AUTOSAR XML (schema 4-0-3)
standard types defined: UInt32, UInt8
package /AUTOSAR_Platform/DataConstrs
  range DC_UInt8: raw 0..255
package /PATAC/MSM/ComponentTypes
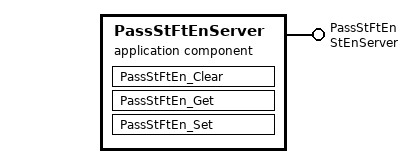
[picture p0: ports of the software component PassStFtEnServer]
  application sw component type PassStFtEnServer
    provide port PassStFtEn: provided-com-specs=[{operation=Clear, queue-length=1}, {operation=Get, queue-length=1}, {operation=Set, queue-length=1}], provided-interface=StEnServer
    behavior PassStFtEnServer_InternalBehavior
      operation invoked event OIT_PassStFtEn_Clear_PassStFtEn_Clear: start-on-event=PassStFtEn_Clear, operation=PassStFtEn.Clear
      operation invoked event OIT_PassStFtEn_GetEnBit_PassStFtEn_Get: start-on-event=PassStFtEn_Get, operation=PassStFtEn.Get
      operation invoked event OIT_PassStFtEn_Set_PassStFtEn_Set: start-on-event=PassStFtEn_Set, operation=PassStFtEn.Set
      runnable PassStFtEn_Clear
      runnable PassStFtEn_Get
      runnable PassStFtEn_Set
  swc implementation PassStFtEnServer_Implementation: behavior=PassStFtEnServer_InternalBehavior
    code-descriptors:
      code Default: artifact-descriptors=autosar-engineering-object={short-label=Default, category=SWSRC}
package /PATAC/MSM/ModeAdjust/PortInterface
  client server interface StEnServer
    operation Clear
      arg data: type=UInt8, direction=IN, server-argument-impl-policy=USE-ARGUMENT-TYPE
    operation Get
      arg data: type=UInt32, direction=OUT, server-argument-impl-policy=USE-ARGUMENT-TYPE
    operation Set
      arg data: type=UInt8, direction=IN, server-argument-impl-policy=USE-ARGUMENT-TYPE
